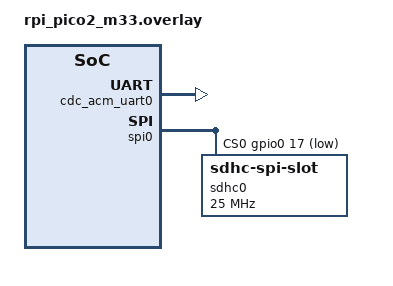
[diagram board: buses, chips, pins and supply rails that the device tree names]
/*
 * Copyright (c) 2024 Auxspace e.V.
 * SPDX-License-Identifier: Apache-2.0
 */

/ {
    chosen {
        zephyr,console = &cdc_acm_uart0;
    };
};

&zephyr_udc0 {
    cdc_acm_uart0: cdc_acm_uart0 {
        compatible = "zephyr,cdc-acm-uart";
        label = "CDC_ACM_0";
    };
};

&spi0 {
    status = "okay";
    cs-gpios = <&gpio0 17 GPIO_ACTIVE_LOW>;

	sdhc0: sdhc@0 {
		compatible = "zephyr,sdhc-spi-slot";
		reg = <0>;
		status = "okay";
		mmc {
			compatible = "zephyr,sdmmc-disk";
			disk-name = "SD";
			status = "okay";
		};
		spi-max-frequency = <25000000>;
	};
};

&gpio0 {
	status = "okay";
};
